# ADuCM410 register map
Vendor: Analog Devices; Series: ADuCM410; File version: 1p0
CPU: CM33 r0p1, little endian, MPU, FPU, 3 interrupt priority bits
Registers are 32-bit, read-write, reset 0x0 unless marked. A register's access mark holds for its fields unless they carry their own. Offsets are from the block's base; [hi:lo] are bit positions.

## WUT
Base 0x40003000
0x00 T4VAL0 — Current Count Value - LS 16 Bits
  [15:0] T4VALL ro — Current Count Low
0x04 T4VAL1 — Current Count Value - MS 16 Bits
  [15:0] T4VALH ro — Current Count High
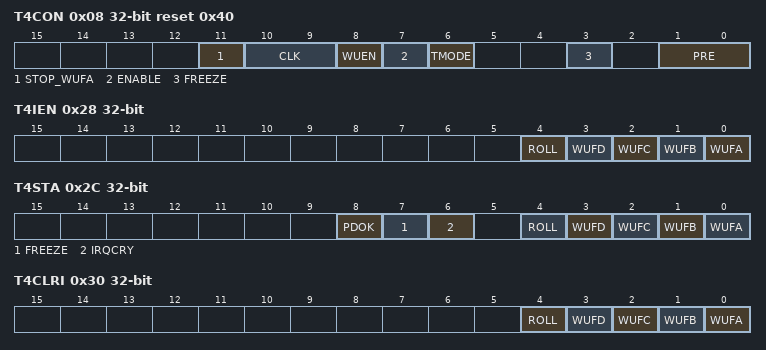
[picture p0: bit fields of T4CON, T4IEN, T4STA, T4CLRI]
0x08 T4CON reset 0x40 — Control Register
  [11] STOP_WUFA range 0x00000000..0x00000001 — Disables Updating Field a Register T4WUFA
  [10:9] CLK — Clock Select
    0=PCLK (PCLK: PCLK (default)); 1=LFOSC (LFOSC: 32 KHz Internal Oscillator); 2=LFOSC1 (LFOSC: 32kHz Internal Oscillator); 3=ECLKIN (ECLKIN: External Clock from P1.0)
  [8] WUEN — Wakeup Enable
    0=DIS (DIS: Cleared by User to Disable the Wake up Timer When the Core Clock is off); 1=EN (EN: Set by User to Enable the Wake up Timer Even When the Core Clock is Off.)
  [7] ENABLE — Timer Enable
    0=DIS (DIS: Disable the Timer (default).); 1=EN (EN: Enable the Timer.)
  [6] TMODE — Timer Mode
    0=PERIODIC (PERIODIC: Cleared by User to Operate in Periodic Mode. in This Mode, the Timer Counts up to T4WUFD); 1=FREERUN (FREERUN: Set by User to Operate in Free Running Mode (default).)
  [3] FREEZE — Freeze Enable
    0=DIS (DIS: Cleared by User to Disable This Feature (default).); 1=EN (EN: Set by User to Enable the Freeze of the High 16-bits After the Lower Bits Have Been Read from T4VAL0. This Ensures That the Software Will Read an Atomic Shot of the Timer. T4VAL1 Unfreezes After It Has Been Read.)
  [1:0] PRE — Prescaler
    0=PREDIV1 (PREDIV1: Source Clock/1 (default). If the Selected Clock Source is PCLK, Then This Setting Results in a Prescaler of 4.); 1=PREDIV16 (PREDIV16: Source Clock/16); 2=PREDIV256 (PREDIV256: Source Clock/256); 3=PREDIV32768 (PREDIV32768: Source Clock/32,768)
0x0C T4INC reset 0xC8 — 12-bit Interval for Wakeup Field a
  [11:0] INTERVAL range 0x00000000..0x00000FFF — Interval for Wakeup Field a
0x10 T4WUFB0 reset 0x1FFF — Wakeup Field B - LS 16 Bits
  [15:0] T4WUFBL range 0x00000000..0x0000FFFF — Wakeup Field B Low
0x14 T4WUFB1 — Wakeup Field B - MS 16 Bits
  [15:0] T4WUFBH range 0x00000000..0x0000FFFF — Wakeup Field B High
0x18 T4WUFC0 reset 0x2FFF — Wakeup Field C - LS 16 Bits
  [15:0] T4WUFCL range 0x00000000..0x0000FFFF — Wakeup Field C Low
0x1C T4WUFC1 — Wakeup Field C - MS 16 Bits
  [15:0] T4WUFCH range 0x00000000..0x0000FFFF — Wakeup Field C High
0x20 T4WUFD0 reset 0x3FFF — Wakeup Field D - LS 16 Bits
  [15:0] T4WUFD0 range 0x00000000..0x0000FFFF — Wakeup Field D Low
0x24 T4WUFD1 — Wakeup Field D - MS 16 Bits
  [15:0] T4WUFDH range 0x00000000..0x0000FFFF — Wakeup Field D High
0x28 T4IEN — Interrupt Enable Register
  [4] ROLL range 0x00000000..0x00000001 — Rollover Interrupt Enable
  [3] WUFD range 0x00000000..0x00000001 — T4WUFD Interrupt Enable
  [2] WUFC range 0x00000000..0x00000001 — T4WUFC Interrupt Enable
  [1] WUFB range 0x00000000..0x00000001 — T4WUFB Interrupt Enable
  [0] WUFA range 0x00000000..0x00000001 — T4WUFA Interrupt Enable
0x2C T4STA — Status Register
  [8] PDOK ro — Enable Bit Synchronized
  [7] FREEZE ro — Timer Value Freeze
  [6] IRQCRY ro — Wakeup Status to Powerdown
  [4] ROLL ro — Rollover Interrupt Flag
  [3] WUFD ro — T4WUFD Interrupt Flag
  [2] WUFC ro — T4WUFC Interrupt Flag
  [1] WUFB ro — T4WUFB Interrupt Flag
  [0] WUFA ro — T4WUFA Interrupt Flag
0x30 T4CLRI — Clear Interrupt Register
  [4] ROLL range 0x00000000..0x00000001 — Rollover Interrupt Clear
  [3] WUFD range 0x00000000..0x00000001 — T4WUFD Interrupt Clear
  [2] WUFC range 0x00000000..0x00000001 — T4WUFC Interrupt Clear
  [1] WUFB range 0x00000000..0x00000001 — T4WUFB Interrupt Clear
  [0] WUFA range 0x00000000..0x00000001 — T4WUFA Interrupt Clear
0x3C T4WUFA0 reset 0x1900 — Wakeup Field a - LS 16 Bits
  [15:0] T4WUFAL range 0x00000000..0x0000FFFF — Wakeup Field a Low
0x40 T4WUFA1 — Wakeup Field a - MS 16 Bits
  [15:0] T4WUFAH range 0x00000000..0x0000FFFF — Wakeup Field a High
